# RS1xxxx register map
Vendor: Silicon Lab Inc.; Series: ARMCM4; File version: 1.2
CPU: CM4 r1p0, little endian, MPU, FPU, 6 interrupt priority bits
Registers are 32-bit, read-write, reset 0x0 unless marked. A register's access mark holds for its fields unless they carry their own. Offsets are from the block's base; [hi:lo] are bit positions; lines under a group give offsets from that group; {n}, {i} and the like mark numbered series; 'fields as' and 'values as' point back to an identical list.

## MCU_CONFIG — MISC CONFIG Register
Base 0x46008000
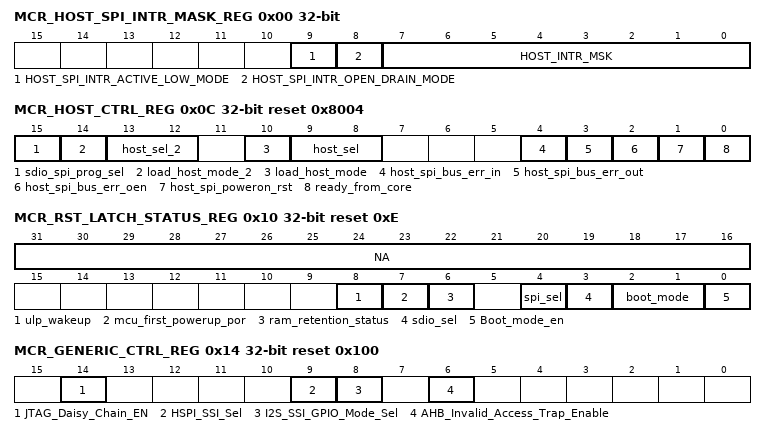
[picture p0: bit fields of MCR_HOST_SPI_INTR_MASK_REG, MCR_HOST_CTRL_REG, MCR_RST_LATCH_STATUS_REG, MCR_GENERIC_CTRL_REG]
0x00 MCR_HOST_SPI_INTR_MASK_REG — MISC CFG HOST INTR MASK
  [9] HOST_SPI_INTR_ACTIVE_LOW_MODE — Writing 1 to this bit configures the host SPI interrupt in active low mode. By default, it will be active high.
  [8] HOST_SPI_INTR_OPEN_DRAIN_MODE — Writing 1 to this bit configures the host SPI interrupt in open drain mode. When open drain mode is enabled and interrupt is configured in active high mode, external PULLDOWN has to be used on the board.
  [7:0] HOST_INTR_MSK — Writing 1 in any bit masks the corresponding interrupt in HOST_INTR_STATUS.
0x04 MCR_HOST_SPI_INTR_SET_REG — MCU host spi interrupt set register
  [7:0] HOST_SPI_INTR_STATUS — Writing '1' to any bit raises an interrupt to SPI host. Writing '1' at the corresponding bit position in MCR_HOST_SPI_INTR_CLR clears the interrupt. Performing read gives HOST_SPI_INTR_STATUS always.
0x08 MCR_HOST_SPI_INTR_CLR_REG — MCU host spi interrupt clear register
  [7:0] HOST_SPI_INTR_CLEAR — Writing '1' to this bit clears the MCR_HOST_SPI_INTR_SET_REG. This register gets cleared in the next clock cycle. Performing read gives HOST_SPI_INTR_STATUS always
0x0C MCR_HOST_CTRL_REG reset 0x8004 — MCU host control register
  [15] sdio_spi_prog_sel — Used to select to use SDIO/ High speed SPI slave
    1=SELECT_SDIO (MCU can access SDIO registers); 0=SELECT_SPI (MCU can access SPI registers)
  [14] load_host_mode_2 — Overrides the Hardware detected Host on 2nd interface.
  [13:12] host_sel_2 — Selects the Host on 2nd Interface
  [10] load_host_mode — Overrides the Hardware detected Host on 1st interface.
    0=H_W_Host_detection (H/W based host detection); 1=S_W_Host_detection (S/W based host detection)
  [9:8] host_sel — Selects the Host on 1st Interface
  [4] host_spi_bus_err_in ro — Host SPI Bus error input.
    0=No_Error (There is no error on Host SPI transmit transaction); 1=Error (There is error in Host SPI transmit transaction)
  [3] host_spi_bus_err_out — Host SPI Bus error output.
    0=No_Error (There is no error on Host SPI receive transaction); 1=Error (There is error in Host SPI receive transaction)
  [2] host_spi_bus_err_oen — Host SPI Bus error output enable. It is active low signal.
    0=Enabled (SPI Bus error output is enabled); 1=Disabled (SPI Bus error output is disabled.)
  [1] host_spi_poweron_rst — This is an active high reset which is used to generate host reset. This has to be enabled only in SPI Host Mode.
  [0] ready_from_core — Indication to the host that bootloading is done. When the reset latch bootload_en is '0' , firmware sets this bit. When hardware bootloading is enabled , this gets set only after bootloading is done. When hardware bootloading is enabled and bootloader is programmed to release the PC from soft reset, firmware sets this bit.
0x10 MCR_RST_LATCH_STATUS_REG ro reset 0xE — MCU reset latch status register
  [31:16] NA
  [8] ulp_wakeup — This bit differentiates between normal power up and ULP wakeup state
    1=ULP_WAKEUP (ULP Based wakeup); 0=NOT_ULP_WAKEUP (Not ULP based wakeup(first powerup))
  [7] mcu_first_powerup_por — This bit indicates MCU first power up status
  [6] ram_retention_status — This bit indicates whether RAM is retained or not.
    1=RAM_RETAINED; 0=RAM_NOT_RETAINED (Ram is not retained)
  [4] spi_sel — This bit indicates the High speed SPI slave host select
    1=SPI_SELECTED (SPI is selected); 0=SPI_NOT_SELECTED (SPI is not selected)
  [3] sdio_sel — This bit indicates the SDIO slave host select
    1=SDIO_SELECTED (SDIO is selected); 0=SDIO_NOT_SELECTED (SDIO is not selected)
  [2:1] boot_mode — Reserved
  [0] Boot_mode_en — This bit is used to indicate if boot mode is enabled.
0x14 MCR_GENERIC_CTRL_REG reset 0x100 — MCU generic control register
  [14] JTAG_Daisy_Chain_EN — This bit has to be set to enable daisy chaining in JTAG
  [9] HSPI_SSI_Sel — Selects if Host spi interface pins are intended for SSI slave else Host SPI
    1=For_SSI_Slave (Host SPI pins used for SSI slave. Host SPI inactive.); 0=For_Host_SPI (Host SPI active)
  [8] I2S_SSI_GPIO_Mode_Sel — When set, GPIO 11,12,13 & 14 are used for SSI in GPIO mode 2.Else I2S
    1=For_SSI (GPIO 11,12,13,14 are used for SSI when configured in GPIO mode 2.); 0=For_I2S (GPIO 11,12,13,14 are used for I2S when configured in GPIO mode 2.)
  [6] AHB_Invalid_Access_Trap_Enable — When this bit is set, trap will be generated to processor in the case an invalid access is done on AHB.
0x18 MCR_AHB_BRIDGE_CTRL_REG — AHB bridge Control Register
  [4] Bypass_Registering_For_AHB_Bridge — When this bit is set, bypass the AHB bus registering in AHB bridge, which is present in between MCU and NWP subsystems. It should be asserted when MCU clock is less than 100MHz
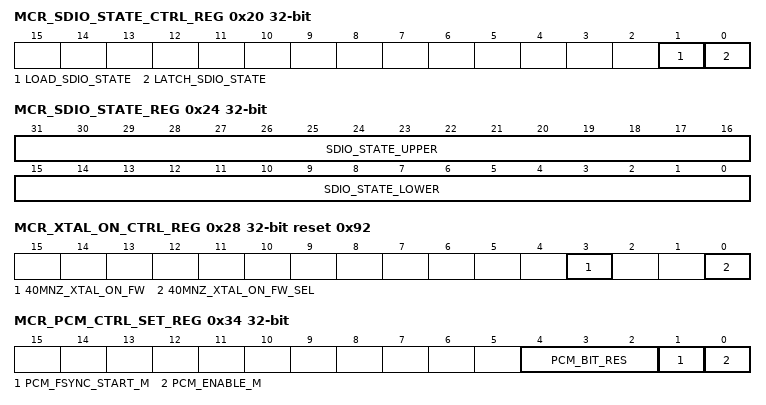
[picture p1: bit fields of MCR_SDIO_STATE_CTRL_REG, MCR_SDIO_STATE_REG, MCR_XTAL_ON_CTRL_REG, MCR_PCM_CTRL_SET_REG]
0x20 MCR_SDIO_STATE_CTRL_REG wo — MCU SDIO state control register
  [1] LOAD_SDIO_STATE — When this bit is set, hardware loads the value in MCR_SDIO_STATE register to SDIO block. The state to be restored has to be loaded to MCR_SDIO_STATE register before setting this. This is done by firmware after coming out of sleep. It is used for ULP Mode State Retention.
  [0] LATCH_SDIO_STATE — When this bit is set, hardware latches the SDIO state into MCR_SDIO_STATE register. This is done by firmware while going to sleep. It is used for ULP Mode State Retention.
0x24 MCR_SDIO_STATE_REG — MCU SDIO status register
  [31:16] SDIO_STATE_UPPER — Upper 16-bits of the SDIO state that is to be loaded into the SDIO block.
  [15:0] SDIO_STATE_LOWER — Lower 16-bits of the SDIO state that is to be loaded into the SDIO block.
0x28 MCR_XTAL_ON_CTRL_REG reset 0x92 — MCU Crystal Control register
  [3] 40MNZ_XTAL_ON_FW — This bit drives the 40MHz crystal ON indication. This bit is considered only if the firmware based driving is enabled using BIT(0) of this register
    1=Crystal_On_Set (crystal ON is set); 0=Crystal_On_Reset (crystal ON is reset)
  [0] 40MNZ_XTAL_ON_FW_SEL — This bit determines the source of 40MHz CRYSTAL ON indication.
    1=Enabled (CRYSTAL ON is controlled by firmware through BIT(3) of this register.); 0=Disabled (CRYSTAL ON is controlled by the sleep state machine and the XTAL_ON_IN coming to the chip. It is asserted whenever there is an indication from either of the clients.)
0x2C MCR_SW_SCRATCHPAD_SET_REG — MCU software scratch pad set register
  [31:0] SOFTWARE_SCRATCHPAD_SET — This register is used by software for storing information. It does not affect anything in the hardware.
    1=Writing_1 (To any of the bits sets the corresponding bit in the soft register.); 0=Writing_0 (has no effect on this register.)
0x30 MCR_SW_SCRATCHPAD_CLEAR_REG — MCU software scratch pad clear register
  [31:0] SOFTWARE_SCRATCHPAD_CLEAR — This register is used by software for storing information. It does not affect anything in the hardware.
    1=Writing_1 (to any of the bits clears the corresponding bit in the soft register.); 0=Writing_0 (has no effect on this register.)
0x34 MCR_PCM_CTRL_SET_REG — MCU PCM interface control set register
  [4:2] PCM_BIT_RES — The bit-resolution of the data on PCM. 3'b000 - 8-bit 3'b001 - 12-bit 3'b010 - 16-bit, 3'b011 - 24-bit 3'b1xx - 32-bit
  [1] PCM_FSYNC_START_M — This bit has to be programmed according to when the MS bit of the PCM data is driven w.r.t. the fsync signal of PCM.
    0=READ_0 (The MS bit of data is driven one clock cycle after fsync goes high.); 1=READ_1 (The MS bit of data is driven in the same clock cycle as fsync going high.); 0=WRITE_0 (has no effect on this register.); 1=WRITE_1 (Writing a '1' to any of the bits sets the corresponding bit in the soft register)
  [0] PCM_ENABLE_M — Enable/disable PCM mode of I2S interface. When PCM is enabled,I2S is disabled and vice versa
    0=READ_0 (PCM mode is disabled and I2S mode is enabled. This programming is in addition to the other GPIO level programming to enable I2S mode.); 1=READ_1 (PCM mode is enabled and I2S mode is disabled. This programming is valid only when the GPIO signals are programmed for I2S mode.); 0=WRITE_0 (has no effect on this register.); 1=WRITE_1 (Writing a '1' to any of the bits sets the corresponding bit in the soft register)
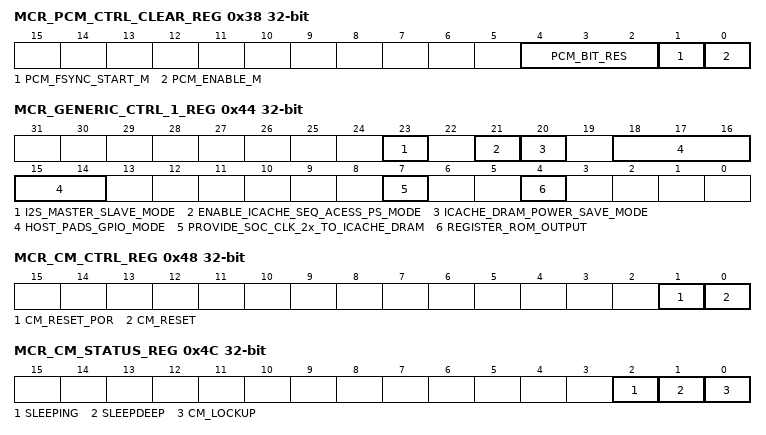
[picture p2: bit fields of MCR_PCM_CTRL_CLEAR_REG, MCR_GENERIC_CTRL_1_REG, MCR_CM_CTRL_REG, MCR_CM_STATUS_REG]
0x38 MCR_PCM_CTRL_CLEAR_REG — MCU PCM interface control clear register
  [4:2] PCM_BIT_RES — Setting the bits clear the pcm_bit_res. Writing '0' has no effect.
  [1] PCM_FSYNC_START_M — Setting bit 1 clear the pcm_fsync_start. Writing '0' has no effect
  [0] PCM_ENABLE_M — Setting bit clears the pcm_enable_m. Writing '0' has no effect
0x44 MCR_GENERIC_CTRL_1_REG — MCU generic control register1
  [23] I2S_MASTER_SLAVE_MODE ro — 0 – I2S/I2S PCM act as slave,1 I2S/I2S PCM act as master
  [21] ENABLE_ICACHE_SEQ_ACESS_PS_MODE — When this bit is set, power save is enabled and a icache read that is sequential to the previous cache read of the same line is saved in local buffer and accessed
  [20] ICACHE_DRAM_POWER_SAVE_MODE — When this bit is set, only half performance is valid with 1x clock.(Data two cycles after clock). Full performance is valid with 2x clock to icache dram
  [18:14] HOST_PADS_GPIO_MODE — Control bit for 5 pins to use it either as host pin or gpio pin. Pins from 30 to 26 are controlled by these bits respectively.
    0=Disabled (HOST mode); 1=Enabled (GPIO mode)
  [7] PROVIDE_SOC_CLK_2x_TO_ICACHE_DRAM ro — When set, twice the frequency of soc clk will be provided to icache dram,. When zero, normal soc_clk is given.
  [4] REGISTER_ROM_OUTPUT — When set, the ready and read data from ROM will be registered. It should be asserted when MCU clock is greater than 100MHz.
0x48 MCR_CM_CTRL_REG — MCU cortex M4 control register
  [1] CM_RESET_POR ro — Status of cm_reset_por can be seen on this bit.
  [0] CM_RESET — Writing 1 both POR and non regions of M4 will be under reset,writing 0 both out of reset
0x4C MCR_CM_STATUS_REG ro — MCU cortex M4 status register
  [2] SLEEPING — When high, indicates the Cortex M4 is in sleeping state
  [1] SLEEPDEEP — When high, indicates the Cortex M4 is in deep sleep state
  [0] CM_LOCKUP — When high, indicates the Cortex M4 is in LOCKUP state
0x50 MCR_CHIP_DEVICE_ID_REG ro reset 0x9117 — MCU chip device ID register
  [15:0] DEVICE_ID — It gives the device ID of the chip. Device ID is 9117.
0x54 MCR_CHIP_VER_NO_REG ro — MCU chip version ID register
  [7:0] VER_NO — Indicates the revision number of the chip.
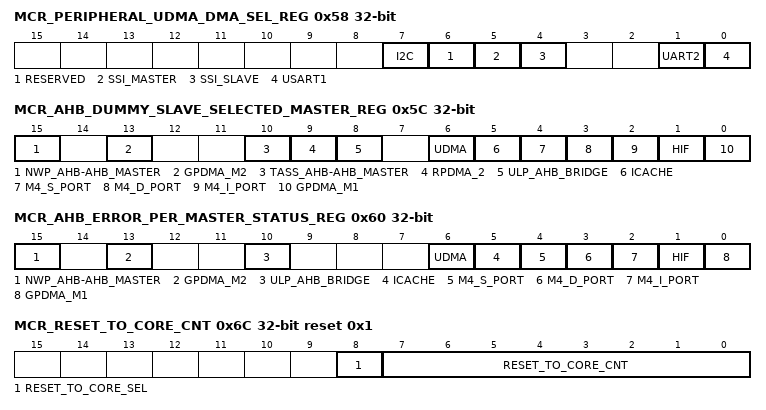
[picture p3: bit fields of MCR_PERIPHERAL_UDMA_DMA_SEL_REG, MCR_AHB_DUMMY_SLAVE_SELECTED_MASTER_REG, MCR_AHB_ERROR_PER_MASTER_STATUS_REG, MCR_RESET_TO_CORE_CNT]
0x58 MCR_PERIPHERAL_UDMA_DMA_SEL_REG — MCU DMA peripheral selection register
  [7] I2C — When set, ack from udma will go to the I2C, else ack from GPDMA will go.
    0=NOT_SET (ACK from udma will go to GPDMA); 1=SET (ACK from udma will go to I2C)
  [6] RESERVED — Rserved
  [5] SSI_MASTER — When set, ack from udma will go to the SSI master, else ack from GPDMA will go.
    0=NOT_SET (ACK from udma will go to GPDMA); 1=SET (ACK from udma will go to SSI Master)
  [4] SSI_SLAVE — When set, ack from udma will go to the SSI, else ack from GPDMA will go.
    0=NOT_SET (ACK from udma will go to GPDMA); 1=SET (ACK from udma will go to SSI)
  [1] UART2 — When set, ack from udma will go to the uart2, else ack from GPDMA will go.
    0=NOT_SET (ACK from udma will go to GPDMA); 1=SET (ACK from udma will go to UART2)
  [0] USART1 — When set, ack from udma will go to the uart1, else ack from GPDMA will go.
    0=NOT_SET (ACK from udma will go to GPDMA); 1=SET (ACK from udma will go to UART1)
0x5C MCR_AHB_DUMMY_SLAVE_SELECTED_MASTER_REG — Hardware sets bit in this register,Firmware resets bits in this register by writing zero
  [15] NWP_AHB-AHB_MASTER — Bit is set, When the NWP AHB-AHB bridge master is trying to access the wrong slave address.
  [13] GPDMA_M2 — Bit is set, When the GPDMA AHB master2 is trying to access the wrong slave address
  [10] TASS_AHB-AHB_MASTER — Bit is set, when TASS AHB is trying to access the wrong slave address.
  [9] RPDMA_2 — Bit is set,when RPDMA M2 is trying to access the wrong slave address.
  [8] ULP_AHB_BRIDGE — Bit is set, when ULP AHB is trying to access the wrong slave address.
  [6] UDMA — Bit is set, When the uDMA AHB master is trying to access the wrong slave address
  [5] ICACHE — Bit is set,When the MCU Icache AHB master is trying to access the wrong slave address.
  [4] M4_S_PORT — Bit is set,When the Cortex M4 S-port AHB master is trying to access the wrong slave address.
  [3] M4_D_PORT — Bit is set,When the Cortex M4 D-port AHB master is trying to access the wrong slave address.
  [2] M4_I_PORT — Bit is set,When the Cortex M4 I-port AHB master is trying to access the wrong slave address.
  [1] HIF — Bit is set,When the HIF AHB master is trying to access the wrong slave address.
  [0] GPDMA_M1 — Bit is set When the GPDMA AHB master1 is trying to access the wrong slave address.
0x60 MCR_AHB_ERROR_PER_MASTER_STATUS_REG — Hardware sets bit in this register,Firmware resets bits in this register by writing zero
  [15] NWP_AHB-AHB_MASTER — Bit is set, When the NWP AHB-AHB bridge master is getting error response.
  [13] GPDMA_M2 — Bit is set, When the GPDMA AHB master2 is getting error response.
  [10] ULP_AHB_BRIDGE — Bit is set, When the ULP AHB-AHB bridge master is getting error response.
  [6] UDMA — Bit is set, When the uDMA AHB master is getting error response.
  [5] ICACHE — Bit is set, When the MCU Icache AHB master is getting error response.
  [4] M4_S_PORT — Bit is set, When the Cortex M4 S-port AHB master is getting error response.
  [3] M4_D_PORT — Bit is set,When the Cortex M4 D-port AHB master is getting error response.
  [2] M4_I_PORT — Bit is set, When the Cortex M4 I-port AHB master is getting error response.
  [1] HIF — Bit is set, When the HIF AHB master is getting error response.
  [0] GPDMA_M1 — Bit is set,When the GPDMA AHB master1 is getting error response.
0x68 MCR_I2S_LOOP_BACK_REG — MCU I2S loopback enable register
  [14] I2S_LOOP_BACK_MODE — Enables MCU I2S loop back mode
0x6C MCR_RESET_TO_CORE_CNT reset 0x1 — MCU reset to core register
  [8] RESET_TO_CORE_SEL — 1: host/debugger reset will be synchronized to sleep clock and used 0: host/debugger reset will be synchronized to soc clock and used
  [7:0] RESET_TO_CORE_CNT — This fields hold the reset active duration in number of clocks.
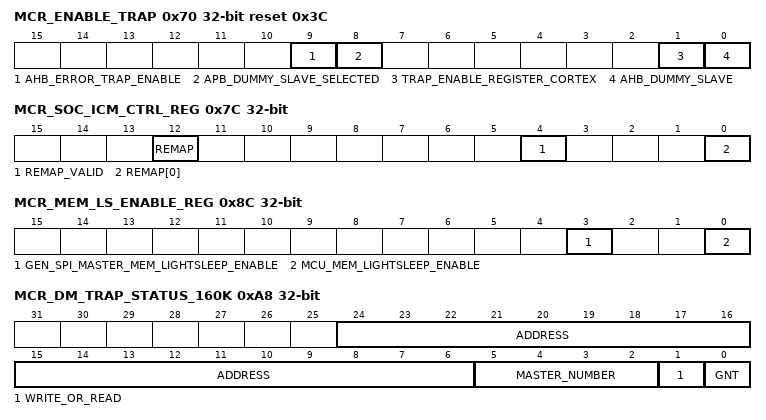
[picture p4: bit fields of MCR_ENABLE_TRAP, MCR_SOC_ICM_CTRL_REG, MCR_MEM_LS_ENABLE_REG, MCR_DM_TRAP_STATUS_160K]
0x70 MCR_ENABLE_TRAP reset 0x3C — MCU enable trap register
  [9] AHB_ERROR_TRAP_ENABLE — When set, ahb error trap is enabled
  [8] APB_DUMMY_SLAVE_SELECTED — When set, any of the master is trying to access the wrong peripheral address.
  [1] TRAP_ENABLE_REGISTER_CORTEX — Enable the trap for cortex.
  [0] AHB_DUMMY_SLAVE ro — AHB dummy slave is selected in cortex
0x74 MCR_SPARE_REG — MCU M4SS spare register
0x7C MCR_SOC_ICM_CTRL_REG — MCU SOC ICM control register
  [12] REMAP ro — Internal logic signal for (remap_valid && remap[0]),This bit is going to AHB ICM input
  [4] REMAP_VALID — Need to set If remap feature is required, along with remap[0].
  [0] REMAP[0] — When remap[0] == 1, the address space for rom will be reduced from 0x003F_FC00 to 0x003F_FFFF and qspi address space will add become 0x0800_0000 to 0x0BFF_FFFF and 0x0030_0000 to 0x003F_FBFF
0x8C MCR_MEM_LS_ENABLE_REG — MCU memory light sleep enable register
  [3] GEN_SPI_MASTER_MEM_LIGHTSLEEP_ENABLE — Must set this bit along with bit[0] of this register to make GSPI FIFO memories enter into light sleep
  [0] MCU_MEM_LIGHTSLEEP_ENABLE — Must set this bit to enable Light Sleep mode for any memory in MCU
0x90 MCR_DM_TRAP_ENABLE_REG_160K — MCU DM trap enable register for memory set 160K
  [11:0] ENABLE_BITS — LSB corresponds to 0th bank in the particular set. A '1' in any bit position indicates that if through that port that bank access , a trap will be generated
0x94 MCR_DMA_WR_TRAP_ENABLE_REG_160K — MCU DM write trap enable register for memory set 160K
  [11:0] ENABLE_BITS — LSB corresponds to oth bank in the particular set. A '1' in any bit position indicates that if through that port that bank access , a trap will be generated
0x98 MCR_DMA_RD_TRAP_ENABLE_REG_160K — MCU DM read trap enable register for memory set 160K
  fields as MCR_DMA_WR_TRAP_ENABLE_REG_160K
0x9C MCR_AHB_MASTER_TRAP_ENABLE_REG_160K — MCU AHB master trap enable register for memory set 160K
  [15:0] TRAP_ENABLE_BITS_PER_MASTER_FOR_MEMORY_SET_160K ro — '1' on a particular bit position indicates that access by that master to a trap enable bank will generate trap otherwise if it is '0' it won't generate a trap if it is accessing a trap enable bank. The masking is for UM1 transactions indicated in DMA_WR_TRAP_ENABLE_REG_160K , DMA_WR_TRAP_ENABLE_REG_160K .
0xA0 MCR_AHB_MASTER_TRAP_ENABLE_REG_64K0 — MCU AHB master trap enable register for memory set 64K0
  [31:16] TRAP_ENABLE_BITS_PER_MASTER_FOR_MEMORY_SET_64K0 — '1' on a particular bit position indicates that access by that master to a trap enable bank will generate trap otherwise if it is '0' it won't generate a trap if it is accessing a trap enable bank. The masking is for UM1 transactions indicated in DMA_WR_TRAP_ENABLE_REG_64K0, DMA_WR_TRAP_ENABLE_REG_64K0
0xA4 MCR_ASYNC_TRAP_DETECTED_160K — MCU Async trap detected register for memory set 160K
  [0] Async_trap_detected_cortex — if set indiacates trap has been detected by cortex,firmware should write this as 1 to clear it
0xA8 MCR_DM_TRAP_STATUS_160K ro — MCU DM trap status register for memory set 160K
  [24:6] ADDRESS — The address for which the read or write request came on dm port.
  [5:2] MASTER_NUMBER — The number of the master which requested the transaction.
  [1] WRITE_OR_READ — 1=write request,0=read request
  [0] GNT — The grant signal for pm port of unified memory
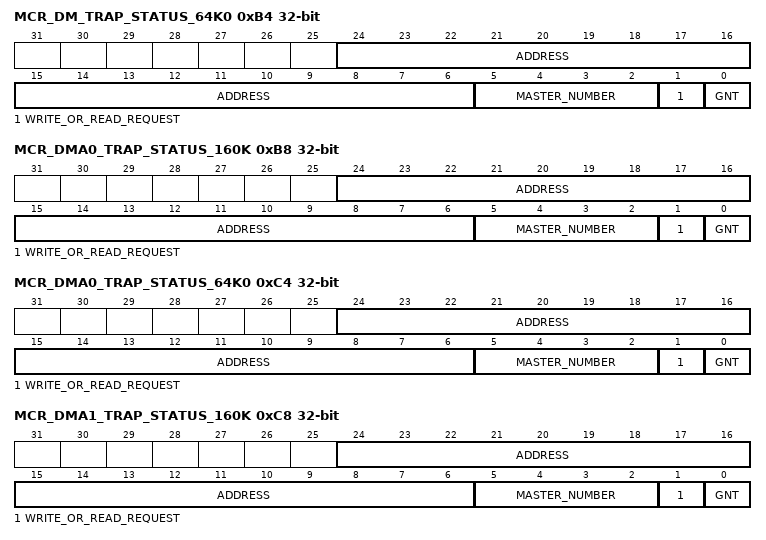
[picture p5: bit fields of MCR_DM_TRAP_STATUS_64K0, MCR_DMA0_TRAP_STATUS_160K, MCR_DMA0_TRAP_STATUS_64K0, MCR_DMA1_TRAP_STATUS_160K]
0xB4 MCR_DM_TRAP_STATUS_64K0 ro — MCU DM trap status register for memory set 64K0
  [24:6] ADDRESS — The address for which the read or write request came on dm port.
  [5:2] MASTER_NUMBER — The number of the master which requested the transaction.
  [1] WRITE_OR_READ_REQUEST — 1=write request, 0=read request
  [0] GNT — The grant signal for pm port of unified memory
0xB8 MCR_DMA0_TRAP_STATUS_160K ro — MCU DMA0 Trap Status Register for memory set 160K
  [24:6] ADDRESS — The address for which the read or write request came on dm port.
  [5:2] MASTER_NUMBER — The number of the master which requested the transaction.
  [1] WRITE_OR_READ_REQUEST — 1=write request, 0=read request
  [0] GNT — The grant signal for dma0 port of unified memory.
0xC4 MCR_DMA0_TRAP_STATUS_64K0 ro — MCU DMA0 Trap Status Register for memory set 64K0
  [24:6] ADDRESS — The address for which the read or write request came on dma0 port.
  [5:2] MASTER_NUMBER — The number of the master which requested the transaction.
  [1] WRITE_OR_READ_REQUEST — 1=write request,0=read request
  [0] GNT — The grant signal for dma0 port of unified memory.
0xC8 MCR_DMA1_TRAP_STATUS_160K ro — MCU DMA1 trap status register for memory set 160K
  [24:6] ADDRESS — The address for which the read or write request came on dma1 port.
  [5:2] MASTER_NUMBER — The number of the master which requested the transaction.
  [1] WRITE_OR_READ_REQUEST — 1=write request,0=read request
  [0] GNT — The grant signal for dma1 port of unified memory.
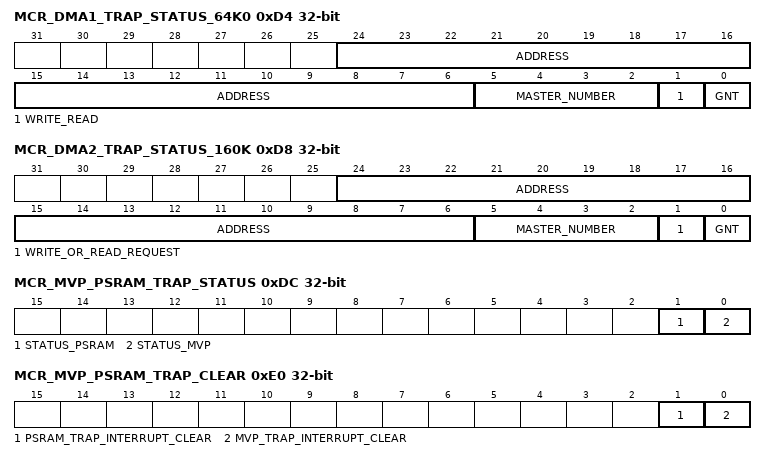
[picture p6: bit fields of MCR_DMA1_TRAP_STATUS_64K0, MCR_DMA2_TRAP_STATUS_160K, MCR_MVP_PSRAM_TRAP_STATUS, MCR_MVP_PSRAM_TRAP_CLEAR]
0xD4 MCR_DMA1_TRAP_STATUS_64K0 ro — MCU DMA1 trap status register for memory set 64K0
  [24:6] ADDRESS — The address for which the read or write request came on dma1 port.
  [5:2] MASTER_NUMBER — The number of the master which requested the transaction.
  [1] WRITE_READ — 1=write request,0=read request
  [0] GNT — The grant signal for dma1 port of unified memory.
0xD8 MCR_DMA2_TRAP_STATUS_160K ro — MCU DMA2 trap status register for memory set 160K
  [24:6] ADDRESS — The address for which the read or write request came on dma2 port.
  [5:2] MASTER_NUMBER — The number of the master which requested the transaction.
  [1] WRITE_OR_READ_REQUEST — 1=write request,0=read request
  [0] GNT — The grant signal for dma2 port of unified memory.
0xDC MCR_MVP_PSRAM_TRAP_STATUS ro — MCU MVP PSRAM trap status register
  [1] STATUS_PSRAM — Tells the status of unauthorized access to PSRAM
  [0] STATUS_MVP — Tells the status of unauthorized access to MVP
0xE0 MCR_MVP_PSRAM_TRAP_CLEAR — MCU MVP PSRAM trap clear register
  [1] PSRAM_TRAP_INTERRUPT_CLEAR — Clears the interrupt for PSRAM trap
  [0] MVP_TRAP_INTERRUPT_CLEAR — Clears the interrupt for MVP trap
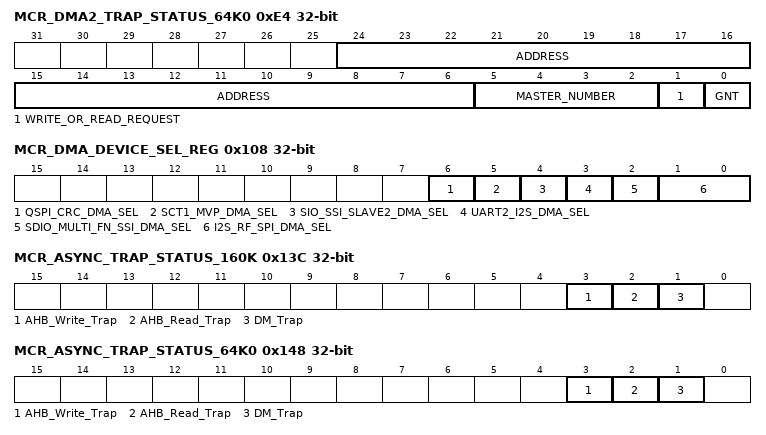
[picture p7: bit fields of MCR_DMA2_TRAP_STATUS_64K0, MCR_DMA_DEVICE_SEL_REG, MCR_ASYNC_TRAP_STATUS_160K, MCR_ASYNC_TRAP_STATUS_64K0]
0xE4 MCR_DMA2_TRAP_STATUS_64K0 ro — MCU DMA2 trap status register for memory set 64K0
  fields as MCR_DMA2_TRAP_STATUS_160K
0x108 MCR_DMA_DEVICE_SEL_REG — MCU DMA device select register
  [6] QSPI_CRC_DMA_SEL — To select between qspi and crc slave 2 flow control signals
    0=CRC_Flow_Control; 1=QSPI_Flow_Control (Selects QSPI flow control)
  [5] SCT1_MVP_DMA_SEL — To select between sct and mvp flow control signals
    0=SCT_Flow_Control (Selects SCT flow control); 1=MVP_Flow_Control (Selects MVP flow control)
  [4] SIO_SSI_SLAVE2_DMA_SEL — To select between sio and ssi slave 2 flow control signals
    1=SIO_Flow_Control (selects SIO flow control); 0=SSI2_SLAVE_FLOW_CONTROL (Selects SSI2 slave flow control)
  [3] UART2_I2S_DMA_SEL — To select between I2S and UART2 flow control signals
    0=UART2_Flow_Control (selects UART 2 flow control); 1=I2S_Flow_Control (selects I2S flow control)
  [2] SDIO_MULTI_FN_SSI_DMA_SEL — To select between SSI master and sdio flow control signals
    1=SSI_MASTER_SELECT; 0=SDIO_FLOW_CONTROL (SDIO Multifunctional)
  [1:0] I2S_RF_SPI_DMA_SEL — To select between i2s and rf spi dma flow control signals
0x118 MCR_DM_TRAP_ENABLE_REG_64K0 — DM Trap Enable Register for memory set 64K0
  [3:0] Enable_Bits_Per_Bank_Memory_Set_4 — LSB corresponds to 0th bank in the particular set. A '1' in any bit position indicates that if through that port that bank access , a trap will be generated
0x124 MCR_DMA_RD_TRAP_ENABLE_REG_64K0 — DMA Read Trap Enable Register for memory set 64K0
  [7:0] Enable_Bits_Per_Bank_Memory_Set_4 — LSB corresponds to 0th bank in the particular set. A '1' in any bit position indicates that if through that port that bank access , a trap will be generated
0x130 MCR_DMA_WR_TRAP_ENABLE_REG_64K0 — DMA Write Trap Enable Register for memory set 64K0
  fields as MCR_DMA_RD_TRAP_ENABLE_REG_64K0
0x13C MCR_ASYNC_TRAP_STATUS_160K ro — Async Trap Status Register for memory set 160K
  [3] AHB_Write_Trap — Async write trap is detected from other AHB ports
  [2] AHB_Read_Trap — Async read is detected from other AHB ports
  [1] DM_Trap — Async trap is detected from cortex IM port
0x148 MCR_ASYNC_TRAP_STATUS_64K0 ro — Async Trap Status Register for memory set 64k0
  fields as MCR_ASYNC_TRAP_STATUS_160K
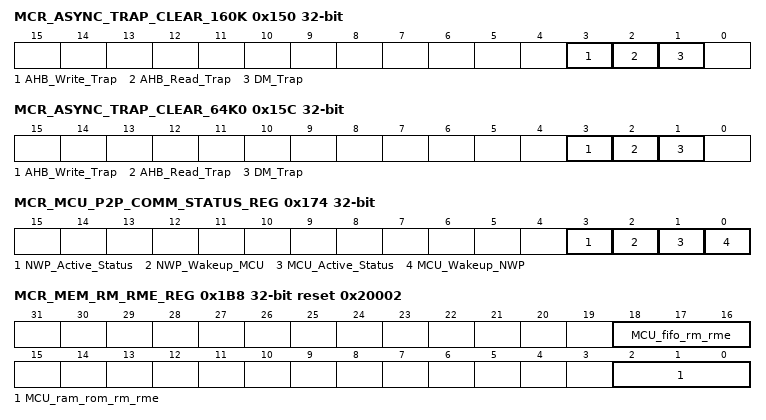
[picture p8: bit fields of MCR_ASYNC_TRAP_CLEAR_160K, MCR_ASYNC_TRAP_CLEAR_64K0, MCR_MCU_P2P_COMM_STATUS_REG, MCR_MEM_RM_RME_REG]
0x150 MCR_ASYNC_TRAP_CLEAR_160K ro — Async Trap Clear Register for memory set 160K
  [3] AHB_Write_Trap — Reading 1 indicates Async write trap is cleared from other AHB ports
    1=Aynch_Write_Trap_Cleared (Async read is cleared from other AHB ports)
  [2] AHB_Read_Trap — Reading 1 indiacates Async read is cleared from other AHB ports
    1=Aynch_Read_Cleared (Async read is cleared from other AHB ports)
  [1] DM_Trap — Reading 1 Indicates Async trap is cleared from cortex IM port
    1=Aynch_Trap_Cleared (Async trap is cleared from cortex IM port)
0x15C MCR_ASYNC_TRAP_CLEAR_64K0 ro — Async Trap Clear Register for memory set 64K0
  fields as MCR_ASYNC_TRAP_CLEAR_160K
0x164 MCR_ASYNC_TRAP_DETECTED_64K0 — Async Trap Detected Register for memory set 64K0
  [0] Async_Trap_Detected_Cortex — This will give you the indication that trap has been detected by cortex. Firmware has to write this bit as '1' so that the asyn_trap can be cleared.
0x16C MCR_MCU_P2P_INTR_SET_REG — MCU to NWP P2P Interrupt Set Register
  [15:0] MCU_P2P_INTR_SET — 16 P2P interrupts for communication from MCU to NWP,Each bit is used to clear the interrupt to NWP
    1=WRITE_1 (Raises the Interrupt); 0=WRITE_0 (No effect); 1=READ_1 (Interrupt is raised); 0=READ_0 (Interrupt not raised)
0x170 MCR_MCU_P2P_INTR_CLR_REG — MCU to NWP P2P Interrupt Clear Register
  [15:0] MCU_P2P_INTR_CLR — 16 P2P interrupts for communication from MCU to NWP,Each bit is used to clear the interrupt to NWP
    1=WRITE_1 (Clears the Interrupt); 0=WRITE_0 (No effect); 1=READ_1 (Interrupt is raised); 0=READ_0 (Interrupt not raised)
0x174 MCR_MCU_P2P_COMM_STATUS_REG — MCU to NWP P2P Communication Status Register
  [3] NWP_Active_Status ro — This bit is used to indicate MCU that NWP is active
    1=NWP_Active (NWP is active); 0=NWP_Sleeping (NWP is sleeping)
  [2] NWP_Wakeup_MCU ro — This bit is used to indicate MCU that it should wakeup from sleep
    1=NWP_Wakesup_MCU; 0=No_Operation (MCU is sleeping)
  [1] MCU_Active_Status — This bit is used to indicate NWP that MCU is active
    1=MCU_Active (MCU is active); 0=MCU_Sleeping (MCU is sleeping)
  [0] MCU_Wakeup_NWP — This bit is used to wakeup NWP from sleep.
    1=HIGH (MCU wakesup NWP); 0=LOW (No Operation)
0x178 MCR_NWP_P2P_INTR_MASK_SET_REG reset 0xFFFF — NWP to MCU P2P Interrupt Mask Register
  [15:0] NWP_P2P_INTR_MASK — 16 P2P interrupts for communication from MCU to NWP,Each bit is used to mask the NWP P2P interrupt
    1=Mask_NWP_P2P_Interrupt (Masks the NWP P2P Interrupt); 0=Not_Raised
0x17C MCR_NWP_P2P_INTR_MASK_CLR_REG reset 0xFFFF — NWP to MCU P2P Interrupt Unmask Register
  [15:0] NWP_P2P_INTR_UNMASK — 16 P2P interrupts for communication from MCU to NWP,Each bit is used to unmask the NWP P2P interrupt
    1=Unmask_NWP_P2P_Interrupt (unmasks the NWP P2P Interrupt); 0=Not_Raised
0x180 MCR_NWP_P2P_INTR_CLR_REG — NWP to MCU P2P Interrupt Clear Register
  [15:0] NWP_P2P_INTR_CLR — 16 P2P interrupts for communication from MCU to NWP,Each bit is used to clear the interrupt to NWP
    1=WRITE_1 (Clears the Interrupt for MCU instantly); 0=WRITE_0 (No effect); 1=READ_1 (Interrupt is raised); 0=READ_0 (Interrupt not raised)
{0x184+8i} MCR_PERI_INTR_MASK_REGn[{i}] (i=0..3) group — MCR_PERI_INTR_MASK_SET_TH0_REG (0-3) and MCR_PERI_INTR_MASK_CLR_TH0_REG (0-3)
  0x00 MCR_PERI_INTR_MASK_SET_TH_n__REG reset 0x1FFFFFFF — Mask Register for MCU HP Peripheral Interrupts going to NWP on Thread
    [28:0] MCU_PERI_MSK_SET — Each bit is used to mask the respective MCU HP peripheral interrupt.
      0=No_Effect_Write (Writing a zero into this has no effect.); 1=Masks_Interrupts_write (Masks the interrupt); 1=Interrupt_masked_read (Interrupt is masked); 0=Interrupt_Not_Masked_read
  0x04 MCR_PERI_INTR_MASK_CLR_TH_n__REG reset 0x1FFFFFFF — Unmask Register for MCU HP Peripheral Interrupts going to NWP on Thread
    [28:0] MCU_PERI_MSK_CLR — Each bit is used to unmask the respective MCU HP peripheral interrupt.
      0=No_Effect_Write (Writing a zero into this has no effect.); 1=Unmasks_Interrupt_write (Unmasks the interrupt); 1=Interrupt_masked_read (Interrupt is masked); 0=Interrupt_Not_Masked_read
{0x1A4+4i} MCR_PERI_INTR_STS_THn_REG[{i}] (i=0..3) group — MCR_PERI_INTR_STS_TH_REG (0-3)
  0x00 MCR_PERI_INTR_STS_TH_n__REG ro reset not defined — Status Register for MCU HP Peripheral Interrupts going to NWP on Thread
    [28:0] MCU_PERI_INTR_STATUS — If bit m of (28:0) is 1, then the mth MCU HP peripheral interrupt is not masked and is been raised in thread
      1=MCU_HP_Peripheral_1_Not_Masked (MCU HP peripheral 1 interrupt not masked); 2=MCU_HP_Peripheral_2_Not_Masked (MCU HP peripheral 2 interrupt not masked); 4=MCU_HP_Peripheral_3_Not_Masked (MCU HP peripheral 3 interrupt not masked); 8=MCU_HP_Peripheral_4_Not_Masked (MCU HP peripheral 4 interrupt not masked); 16=MCU_HP_Peripheral_5_Not_Masked (MCU HP peripheral 5 interrupt not masked); 32=MCU_HP_Peripheral_6_Not_Masked (MCU HP peripheral 6 interrupt not masked); 64=MCU_HP_Peripheral_7_Not_Masked (MCU HP peripheral 7 interrupt not masked); 128=MCU_HP_Peripheral_8_Not_Masked (MCU HP peripheral 8 interrupt not masked); 0x100=MCU_HP_Peripheral_9_Not_Masked (MCU HP peripheral 9 interrupt not masked); 0x200=MCU_HP_Peripheral_10_Not_Masked (MCU HP peripheral 10 interrupt not masked); 0x400=MCU_HP_Peripheral_11_Not_Masked (MCU HP peripheral 11 interrupt not masked); 0x800=MCU_HP_Peripheral_12_Not_Masked (MCU HP peripheral 12 interrupt not masked); 0x1000=MCU_HP_Peripheral_13_Not_Masked (MCU HP peripheral 13 interrupt not masked); 0x2000=MCU_HP_Peripheral_14_Not_Masked (MCU HP peripheral 14 interrupt not masked); 0x4000=MCU_HP_Peripheral_15_Not_Masked (MCU HP peripheral 15 interrupt not masked); 0x8000=MCU_HP_Peripheral_16_Not_Masked (MCU HP peripheral 16 interrupt not masked); 0x10000=MCU_HP_Peripheral_17_Not_Masked (MCU HP peripheral 17 interrupt not masked); 0x20000=MCU_HP_Peripheral_18_Not_Masked (MCU HP peripheral 18 interrupt not masked); 0x40000=MCU_HP_Peripheral_19_Not_Masked (MCU HP peripheral 19 interrupt not masked); 0x80000=MCU_HP_Peripheral_20_Not_Masked (MCU HP peripheral 20 interrupt not masked); 0x100000=MCU_HP_Peripheral_21_Not_Masked (MCU HP peripheral 21 interrupt not masked); 0x200000=MCU_HP_Peripheral_22_Not_Masked (MCU HP peripheral 22 interrupt not masked); 0x400000=MCU_HP_Peripheral_23_Not_Masked (MCU HP peripheral 23 interrupt not masked); 0x800000=MCU_HP_Peripheral_24_Not_Masked (MCU HP peripheral 24 interrupt not masked); 0x1000000=MCU_HP_Peripheral_25_Not_Masked (MCU HP peripheral 25 interrupt not masked); 0x2000000=MCU_HP_Peripheral_26_Not_Masked (MCU HP peripheral 26 interrupt not masked); 0x4000000=MCU_HP_Peripheral_27_Not_Masked (MCU HP peripheral 27 interrupt not masked); 0x8000000=MCU_HP_Peripheral_28_Not_Masked (MCU HP peripheral 28 interrupt not masked)
0x1B8 MCR_MEM_RM_RME_REG reset 0x20002 — Memory RM and RME Control Register
  [18:16] MCU_fifo_rm_rme — [18:17] bits are used as RM ports for fifo memories which are internal to peripherals.[16] bit is used as RM enable (RME) for fifo memories which are internal to peripherals.
    values as MCR_HOST_CTRL_REG.host_spi_bus_err_oen
  [2:0] MCU_ram_rom_rm_rme — [2:1] bits are used as RM ports for SRAM memories,[0] bit is used as RM enable (RME) for SRAM memories.
0x1C8 MCR_AHB_MASTER_TRAP_ENABLE_64K1 — AHB Master Trap Enable Register for memory set 64K1
  [31:16] Trap_enable_bits_per_master_64K1 — '1' on a particular bit position indicates that access by that master to a trap enable bank will generate trap otherwise if it is '0' it won't generate a trap if it is accessing a trap enable bank. The masking is for UM1 transactions indicated in DMA_WR_TRAP_ENABLE_REG_64K1, DMA_WR_TRAP_ENABLE_REG_64K1
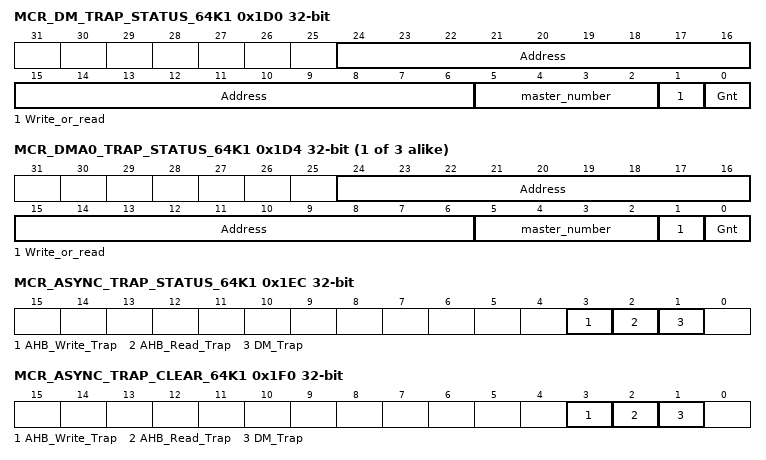
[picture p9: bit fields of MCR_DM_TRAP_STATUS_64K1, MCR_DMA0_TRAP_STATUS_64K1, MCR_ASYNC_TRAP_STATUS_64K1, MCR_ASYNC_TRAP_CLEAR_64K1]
0x1D0 MCR_DM_TRAP_STATUS_64K1 ro — DM Trap Status Register for memory set 64K1
  [24:6] Address — The address for which the read or write request came on dm port.
  [5:2] master_number — The number of the master which requested the transaction.
  [1] Write_or_read — to check whether its read or write request
    0=Read_Request; 1=Write_request
  [0] Gnt — The grant signal for pm port of unified memory.
{0x1D4+4i} MCR_DMA{i}_TRAP_STATUS_64K1 ro (i=0..2) — DMA{i} Trap Status Register for memory set 64K1
  [24:6] Address — The address for which the read or write request came on dm{i} port.
  [5:2] master_number — The number of the master which requested the transaction.
  [1] Write_or_read — to check whether its read or write request
    0=Read_Request; 1=Write_request
  [0] Gnt — The grant signal for pm port of unified memory.
0x1E0 MCR_DM_TRAP_ENABLE_REG_64K1 — DM Trap Enable Register for memory set 64K1
  fields as MCR_DM_TRAP_ENABLE_REG_64K0
0x1E4 MCR_DMA_RD_TRAP_ENABLE_REG_64K1 — DMA Read Trap Enable Register for memory set 64K1
  fields as MCR_DMA_RD_TRAP_ENABLE_REG_64K0
0x1E8 MCR_DMA_WR_TRAP_ENABLE_REG_64K1 — DMA Write Trap Enable Register for memory set 64K1
  fields as MCR_DMA_RD_TRAP_ENABLE_REG_64K0
0x1EC MCR_ASYNC_TRAP_STATUS_64K1 ro — Async Trap Status Register for memory set 64K1
  fields as MCR_ASYNC_TRAP_STATUS_160K
0x1F0 MCR_ASYNC_TRAP_CLEAR_64K1 ro — Async Trap Clear Register for memory set 64K1
  fields as MCR_ASYNC_TRAP_CLEAR_160K
0x1F4 MCR_ASYNC_TRAP_DETECTED_64K1 — Async Trap Detected Register for memory set 64K1
  fields as MCR_ASYNC_TRAP_DETECTED_64K0
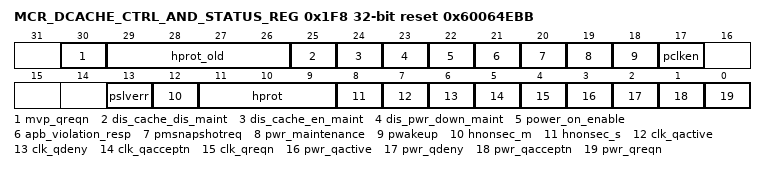
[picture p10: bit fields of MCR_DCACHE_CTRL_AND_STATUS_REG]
0x1F8 MCR_DCACHE_CTRL_AND_STATUS_REG reset 0x60064EBB — Dcache Control and Status Register
  [30] mvp_qreqn — This input is for the MVP q channel interface. (MVP is not using qchannel active low signal)
  [29:26] hprot_old — This signal represents the ahb3 hprot description
  [25] dis_cache_dis_maint — This signal turns off cache disable maintenance.
  [24] dis_cache_en_maint — This signal turns off cache enable maintenance.
  [23] dis_pwr_down_maint — This signal turns off powerdown maintenance.
  [22] power_on_enable — This signal enables the cache automatically after powerup.
  [21] apb_violation_resp — If HIGH,indicates the AHB Cache responds with errors to failed APB accesses by asserting pslverr
  [20] pmsnapshotreq — A trigger signal which initiates the capture of the current value of the statistics counters. Must be a synchronous pulse.
  [19] pwr_maintenance ro — deasserted indicates cache powerdown preparation done.Asserted if powerdown maintenance is ongoing
  [18] pwakeup — Wake up signal,Indicates that there is ongoing activity that is associated with the APB interface
  [17] pclken — The clock enable signal. This signal allows the APB to run on a divided frequency.
  [13] pslverr ro — Indicates a transfer failure
  [12] hnonsec_m ro — Assertion indicates for a Non-secure transfer and Deasserted for a Secure transfer
  [11:9] hprot — Since Dcache is AHB 5 compatible, The remaining signals are included in this register as configurable.
  [8] hnonsec_s — Non-secure transfer indicator,Asserted for a Non-secure transfer and Deasserted for a Secure transfer
  [7] clk_qactive ro — when 1, indicates to the controller that the AHB Cache requires the clock. When 0, the AHB Cache might accept a quiescence request.
  [6] clk_qdeny ro — When 1 indicates that the AHB Cache denies the quiescence request from the clock controller.
  [5] clk_qacceptn ro — When 0, indicates that the AHB Cache accepts the quiescence request from the clock controller.
  [4] clk_qreqn — Active-LOW quiescence request signal driven by the clock controller.
  [3] pwr_qactive ro — 1 indicates to the controller that the AHB Cache needs power,0 indicates the AHB Cache might accept a quiescence request
  [2] pwr_qdeny ro — When 1, indicates that the AHB Cache denies the quiescence request from the power controller
  [1] pwr_qacceptn ro — When 0, indicates that the AHB Cache accepts the quiescence request from the power controller
  [0] pwr_qreqn — Active-LOW quiescence request signal driven by the power controller.
0x1FC MCR_ULP_AHB_BRIDGE_CLK_ENABLE_REG reset 0x1 — ULP AHB-AHB bridge static clock enable register
  [0] ULP_AHB_bridge_clk_enable — Used to enable static clock gating ULP AHB-AHB bridge. Only 32-bit write is allowed into this register.
